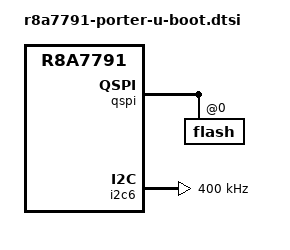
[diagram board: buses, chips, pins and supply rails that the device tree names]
// SPDX-License-Identifier: GPL-2.0
/*
 * Device Tree Source extras for U-Boot for the Porter board
 *
 * Copyright (C) 2018 Marek Vasut <marek.vasut@gmail.com>
 */

&qspi {
	flash@0 {
		spi-tx-bus-width = <1>;
		spi-rx-bus-width = <1>;
	};
};

&i2c6 {
	clock-frequency = <400000>;
};
